# K1921VK035 register map
Vendor: NIIET; Series: K1921VKx; File version: 2.10
Tiny motor control MCU
CPU: CM4 r0p1, little endian, MPU, FPU, 3 interrupt priority bits
Registers are 32-bit, read-write, reset 0x0 unless marked. A register's access mark holds for its fields unless they carry their own. Offsets are from the block's base; lines under a group give offsets from that group; [hi:lo] are bit positions; {n}, {i} and the like mark numbered series; 'fields as' and 'values as' point back to an identical list; <NAME> marks a mode.

## Memory map
0x40000000 ADC size 0x514 — ADC control registers
0x40010000 GPIOA size 0xC04 — GPIO control registers
0x40011000 GPIOB size 0xC04
0x40020000 CAN size 0x3004 — CAN controller registers
0x40021000 CANMSG size 0x804 — CAN Msg registers
0x40030000 MFLASH size 0x7C — Mainflash control registers
0x40040000 SIU size 0x1000 — System integration unit registers
0x40041000 RCU size 0x108 — Reset and clock unit registers
0x40042000 PMU size 0x10 — Power management unit registers
0x40043000 WDT size 0xC04 — Watchdog control registers
0x40044000 DMA size 0x50 — DMA control registers
0x40045000 UART0 size 0x4C — UART control registers
0x40046000 UART1 size 0x4C
0x40047000 SPI size 0x28 — SPI control registers
0x40048000 TMR0 size 0x18 — TMR controller registers
0x40049000 TMR1 size 0x18
0x4004A000 TMR2 size 0x18
0x4004B000 TMR3 size 0x18
0x4004C000 PWM0 size 0xAC — PWM controller registers
0x4004D000 PWM1 size 0xAC
0x4004E000 PWM2 size 0xAC
0x4004F000 QEP size 0x74 — QEP controller registers
0x40050000 I2C size 0x28 — I2C controller registers
0x40051000 ECAP0 size 0x44 — ECAP controller registers
0x40052000 ECAP1 size 0x44
0x40053000 ECAP2 size 0x44

## Interrupts
0 WDT — Watchdog timer interrupt
1 RCU — Reset and clock unit interrupt
2 MFLASH — MFLASH interrupt
3 GPIOA — GPIO A interrupt
4 GPIOB — GPIO B interrupt
{n+5} DMA_CH{n} (DMA) (n=0..15) — DMA channel {n} interrupt
21 TMR0 — Timer 0 interrupt
22 TMR1 — Timer 1 interrupt
23 TMR2 — Timer 2 interrupt
24 TMR3 — Timer 3 interrupt
25 UART0_TD (UART0) — UART0 Transmit Done interrupt
26 UART0_RX (UART0) — UART0 Recieve interrupt
27 UART0_TX (UART0) — UART0 Transmit interrupt
28 UART0_E_RT (UART0) — UART0 Error and Receive Timeout interrupt
29 UART1_TD (UART1) — UART1 Transmit Done interrupt
30 UART1_RX (UART1) — UART1 Recieve interrupt
31 UART1_TX (UART1) — UART1 Transmit interrupt
32 UART1_E_RT (UART1) — UART1 Error and Receive Timeout interrupt
33 SPI_RO_RT (SPI) — SPI RX FIFO overrun and Receive Timeout interrupt
34 SPI_RX (SPI) — SPI Receive interrupt
35 SPI_TX (SPI) — SPI Transmit interrupt
36 I2C — I2C interrupt
37 ECAP0 — ECAP0 interrupt
38 ECAP1 — ECAP1 interrupt
39 ECAP2 — ECAP2 interrupt
40 PWM0 — PWM0 interrupt
41 PWM0_HD (PWM0) — PWM0 HD interrupt
42 PWM0_TZ (PWM0) — PWM0 TZ interrupt
43 PWM1 — PWM1 interrupt
44 PWM1_HD (PWM1) — PWM1 HD interrupt
45 PWM1_TZ (PWM1) — PWM1 TZ interrupt
46 PWM2 — PWM2 interrupt
47 PWM2_HD (PWM2) — PWM2 HD interrupt
48 PWM2_TZ (PWM2) — PWM2 TZ interrupt
49 QEP — QEP interrupt
50 ADC_SEQ0 (ADC) — ADC Sequencer 0 interrupt
51 ADC_SEQ1 (ADC) — ADC Sequencer 1 interrupt
52 ADC_DC (ADC) — ADC Digital Comparator interrupt
{n+53} CAN{n} (CAN) (n=0..15) — CAN{n} interrupt
69 FPU (SIU) — FPU exception interrupt

## SIU — System integration unit registers
Base 0x40040000
0x10 PWMSYNC — PWM syncronization control register
  [10:8] PRESCRST — PWM prescalers reset control
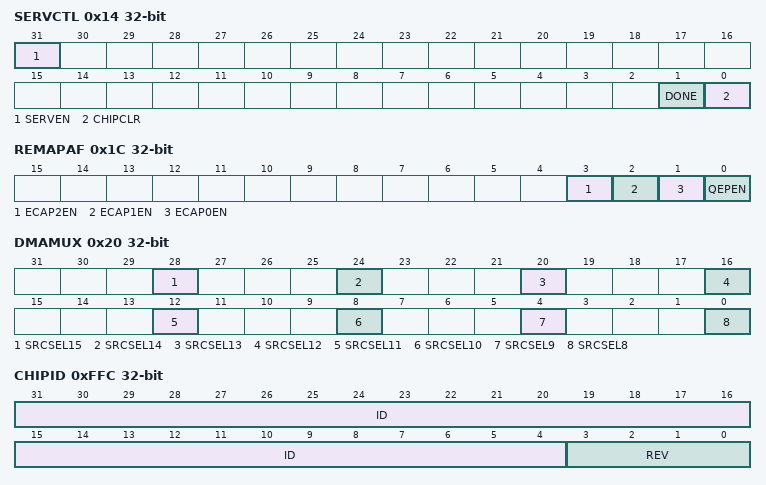
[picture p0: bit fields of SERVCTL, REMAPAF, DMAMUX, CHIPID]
0x14 SERVCTL — Service mode control register
  [31] SERVEN ro
  [1] DONE ro — Status of clear task
  [0] CHIPCLR — On-chip memories full clear task start
0x18 CLKOUTCTL — Clock out control register
  [0] CLKOUTEN — Enable clockout pin
0x1C REMAPAF — QEP altfunc control
  [3] ECAP2EN — Enable ECAP2 altfunc
  [2] ECAP1EN — Enable ECAP1 altfunc
  [1] ECAP0EN — Enable ECAP0 altfunc
  [0] QEPEN — Enable QEP altfunc
0x20 DMAMUX — DMA external requests mux control register
  [28] SRCSEL15 — Request source select for DMA channel 15
    0=PWM2A (request by PWM2A); 1=Reserved (no source)
  [24] SRCSEL14 — Request source select for DMA channel 14
    0=PWM1A (request by PWM1A); 1=Reserved (no source)
  [20] SRCSEL13 — Request source select for DMA channel 13
    0=PWM0A (request by PWM0A); 1=Reserved (no source)
  [16] SRCSEL12 — Request source select for DMA channel 12
    0=TMR3 (request by TMR3); 1=PWM2B (request by PWM2B)
  [12] SRCSEL11 — Request source select for DMA channel 11
    0=TMR2 (request by TMR2); 1=PWM1B (request by PWM1B)
  [8] SRCSEL10 — Request source select for DMA channel 10
    0=TMR1 (request by TMR1); 1=PWM0B (request by PWM0B)
  [4] SRCSEL9 — Request source select for DMA channel 9
    0=TMR0 (request by TMR0); 1=GPIOB (request by GPIOB)
  [0] SRCSEL8 — Request source select for DMA channel 8
    0=QEP (request by QEP); 1=GPIOA (request by GPIOA)
0xFFC CHIPID ro — Chip identifier
  [31:4] ID — Model ID
  [3:0] REV — Revision number

## Licence text in the file
ARM Limited (ARM) is supplying this software for use with Cortex-M processor based microcontroller, but can be equally used for other suitable processor architectures. This file can be freely distributed. Modifications to this file shall be clearly marked. . THIS SOFTWARE IS PROVIDED "AS IS". NO WARRANTIES, WHETHER EXPRESS, IMPLIED. OR STATUTORY, INCLUDING, BUT NOT LIMITED TO, IMPLIED WARRANTIES OF. MERCHANTABILITY AND FITNESS FOR A PARTICULAR PURPOSE APPLY TO THIS SOFTWARE. ARM SHALL NOT, IN ANY CIRCUMSTANCES, BE LIABLE FOR SPECIAL, INCIDENTAL, OR. CONSEQUENTIAL DAMAGES, FOR ANY REASON WHATSOEVER.
